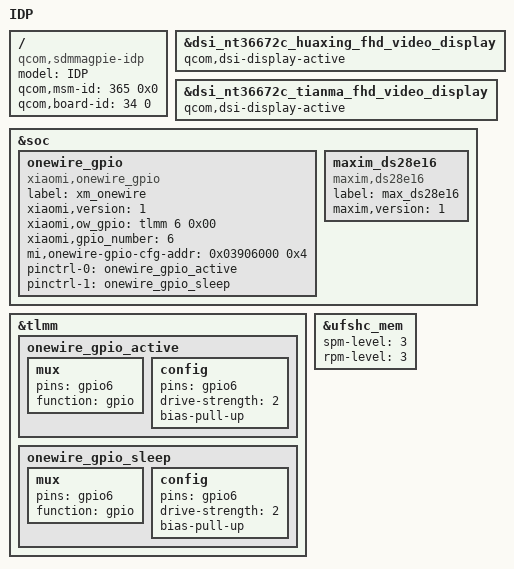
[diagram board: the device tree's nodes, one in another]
/dts-v1/;
/plugin/;

#include <dt-bindings/interrupt-controller/arm-gic.h>
#include <dt-bindings/clock/qcom,camcc-sdmmagpie.h>

#include "sdmmagpie-idp.dtsi"
#include "xiaomi/surya/surya-sdmmagpie-idp-overlay.dtsi"
#include "xiaomi/surya/haptic.dtsi"
#include "xiaomi/surya/touchscreen.dtsi"

/ {
	model = "IDP";
	compatible = "qcom,sdmmagpie-idp", "qcom,sdmmagpie", "qcom,idp";
	qcom,msm-id = <365 0x0>;
	qcom,board-id = <34 0>;
};

&dsi_nt36672c_huaxing_fhd_video_display {
	qcom,dsi-display-active;
};
&dsi_nt36672c_tianma_fhd_video_display {
	qcom,dsi-display-active;
};

&soc {
	onewire_gpio: onewire_gpio {
		compatible = "xiaomi,onewire_gpio";
		label = "xm_onewire";
		xiaomi,version = <1>;
		xiaomi,ow_gpio = <&tlmm 6 0x00>;
		xiaomi,gpio_number = <6>;
		mi,onewire-gpio-cfg-addr = <0x03906000 0x4>;
		pinctrl-names = "onewire_active", "onewire_sleep";
		pinctrl-0 = <&onewire_gpio_active>;
		pinctrl-1 = <&onewire_gpio_sleep>;
		status = "ok";
	};

	maxim_ds28e16: maxim_ds28e16 {
		compatible = "maxim,ds28e16";
		label = "max_ds28e16";
		maxim,version = <1>;
		status = "ok";
	};
};

&tlmm {
	onewire_gpio_active: onewire_gpio_active {
		mux {
			pins = "gpio6";
			function = "gpio";
		};

		config {
			pins = "gpio6";
			drive-strength = <2>;
			bias-pull-up;
		};
	};

	onewire_gpio_sleep: onewire_gpio_sleep {
		mux {
			pins = "gpio6";
			function = "gpio";
		};

		config {
			pins = "gpio6";
			drive-strength = <2>;
			bias-pull-up;
		};
	};
};

&ufshc_mem {
	spm-level = <3>;
	rpm-level = <3>;
};
